# RA6M1 register map
Vendor: Renesas Electronics Corporation; Series: RA6; File version: 1.2
CPU: CM4 r0p1, little endian, MPU, FPU, VTOR, 4 interrupt priority bits
Registers are 8-bit, read-write, reset 0x0 unless marked. A register's access mark holds for its fields unless they carry their own. Offsets are from the block's base; [hi:lo] are bit positions; {n}, {i} and the like mark numbered series.

## DOC — Data Operation Circuit
Base 0x40054100
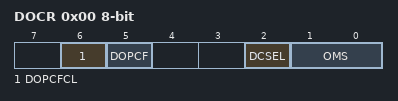
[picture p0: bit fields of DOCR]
0x00 DOCR — DOC Control Register
  [6] DOPCFCL — DOPCF Clear
    0=Maintains the DOPCF flag state; 1=Clears the DOPCF flag
  [5] DOPCF ro — Data Operation Circuit FlagIndicates the result of an operation.
  [2] DCSEL — Detection Condition Select
    0=DOPCF is set when data mismatch is detected; 1=DOPCF is set when data match is detected
  [1:0] OMS — Operating Mode Select
    0=Data comparison mode; 1=Data addition mode; 2=Data subtraction mode; 3=Setting prohibited
0x02 DODIR 16-bit — DOC Data Input Register
  [15:0] DODIR — 16-bit read-write register in which 16-bit data for use in the operations are stored.
0x04 DODSR 16-bit — DOC Data Setting Register
  [15:0] DODSR — This register stores 16-bit data for use as a reference in data comparison mode. This register also stores the results of operations in data addition and data subtraction modes.

## IWDT — Independent Watchdog Timer
Base 0x40044400
0x00 IWDTRR reset 0xFF — IWDT Refresh Register
  [7:0] IWDTRR — The counter is refreshed by writing 0x00 and then writing 0xFF to this register.
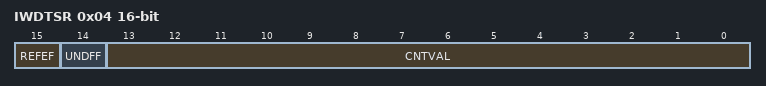
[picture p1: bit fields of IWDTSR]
0x04 IWDTSR 16-bit — IWDT Status Register
  [15] REFEF write-0-clears read-modifies — Refresh Error Flag
    0=Refresh error not occurred; 1=Refresh error occurred
  [14] UNDFF write-0-clears read-modifies — Underflow Flag
    0=Underflow not occurred; 1=Underflow occurred
  [13:0] CNTVAL ro — Counter ValueValue counted by the counter

## KINT — Key Interrupt Function
Base 0x40080000
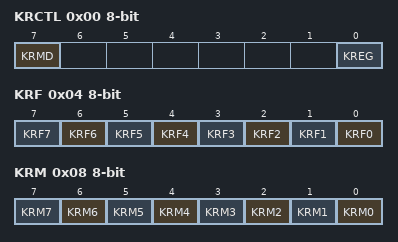
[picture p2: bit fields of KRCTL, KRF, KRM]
0x00 KRCTL — KEY Return Control Register
  [7] KRMD — Usage of Key Interrupt Flags(KR0 to KR7)
    0=Do not use key interrupt flags; 1=Use key interrupt flags
  [0] KREG — Detection Edge Selection (KRF0 to KRF7)
    0=Falling edge; 1=Rising edge
0x04 KRF write-0-clears read-modifies — KEY Return Flag Register
  [all] fields
    0=No interrupt detected; 1=Interrupt detected
  [n] KRF{n} write-0-clears read-modifies (n=0..7) — Key interrupt flag {n}
0x08 KRM — KEY Return Mode Register
  [all] fields
    0=Does not detect key interrupt signal; 1=Detect key interrupt signal
  [n] KRM{n} (n=0..7) — Key interrupt mode control {n}

## WDT — Watchdog Timer
Base 0x40044200
0x00 WDTRR reset 0xFF — WDT Refresh Register
  [7:0] WDTRR — WDTRR is an 8-bit register that refreshes the down-counter of the WDT.
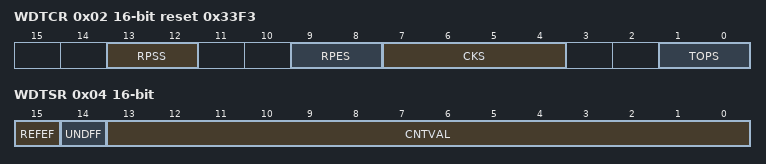
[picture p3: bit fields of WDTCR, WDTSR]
0x02 WDTCR 16-bit reset 0x33F3 — WDT Control Register
  [13:12] RPSS — Window Start Position Selection
    0=25 percent; 1=50 percent; 2=75 percent; 3=100 percent (window start position is not specified)
  [9:8] RPES — Window End Position Selection
    0=75 percent; 1=50 percent; 2=25 percent; 3=0 percent (window end position is not specified)
  [7:4] CKS — Clock Division Ratio Selection
    1=PCLK/4; 4=PCLK/64; 15=PCLK/128; 6=PCLK/512; 7=PCLK/2048; 8=PCLK/8192; other=others (setting prohibited)
  [1:0] TOPS — Timeout Period Selection
    0=1,024 cycles (03FFh); 1=4,096 cycles (0FFFh); 2=8,192 cycles (1FFFh); 3=16,384 cycles (3FFFh)
0x04 WDTSR 16-bit — WDT Status Register
  [15] REFEF write-0-clears read-modifies — Refresh Error Flag
    0=No refresh error occurred; 1=Refresh error occurred
  [14] UNDFF write-0-clears read-modifies — Underflow Flag
    0=No underflow occurred; 1=Underflow occurred
  [13:0] CNTVAL ro — Down-Counter ValueValue counted by the down-counter
0x06 WDTRCR reset 0x80 — WDT Reset Control Register
  [7] RSTIRQS — Reset Interrupt Request Selection
    0=Non-maskable interrupt request or interrupt request output is enabled; 1=Reset output is enabled
0x08 WDTCSTPR reset 0x80 — WDT Count Stop Control Register
  [7] SLCSTP — Sleep-Mode Count Stop Control
    0=Count stop is disabled; 1=Count is stopped at a transition to sleep mode
